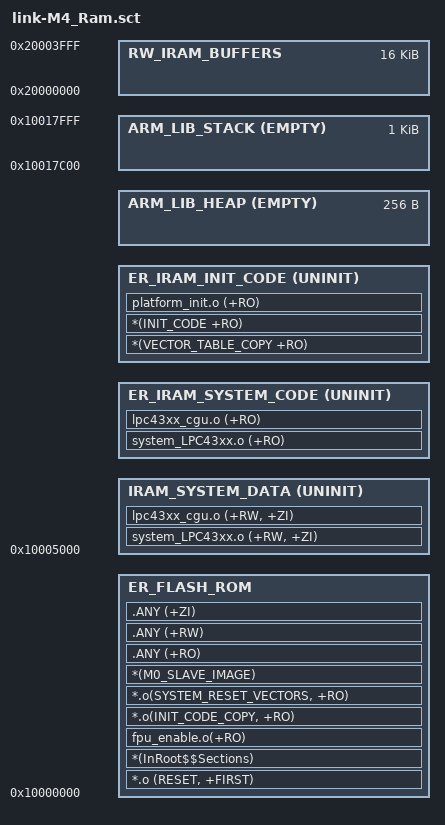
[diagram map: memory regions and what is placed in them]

LR_IRAM 0x10000000 0x18000  {    

  	; code
	ER_FLASH_ROM 0x10000000 {  
   		
		*.o (RESET, +FIRST)
		 
	 	; used as an alias for the ARM library functions 
		; (__main, __scatter, __dc, __*region$$Table etc)
		*(InRoot$$Sections)	 
		
		; enable the fpu as soon as possible if present
		fpu_enable.o(+RO)
		
		; this code copies the initialization routines in ram
		; these are needed to change the PLL settings, the EMC settings
		; are executed from ER_IRAM_SYSTEM_CODE, ER_IRAM_BOOT_CODE 
		*.o(INIT_CODE_COPY, +RO)
		
		; include all system reset vectors
		*.o(SYSTEM_RESET_VECTORS, +RO) 
		
		*(M0_SLAVE_IMAGE)
		
		.ANY (+RO)
		.ANY (+RW)
		.ANY (+ZI) 

	}
	
  	; "SystemData_noInit" section  
	IRAM_SYSTEM_DATA 0x10005000 UNINIT {
  	
		system_LPC43xx.o (+RW, +ZI)
		lpc43xx_cgu.o (+RW, +ZI)			  	
	}

	; these are the runtime locations for the PLL and EMC initialization routines
	; SYSTEM_CODE should likely be kept during the application's lifetime
	; scu and cgu functions could be needed later on
	ER_IRAM_SYSTEM_CODE +0 UNINIT { 

		system_LPC43xx.o (+RO)
		lpc43xx_cgu.o (+RO)
	}

	; these functions are used only during startup
	; eventually this RAM area could be reused during the application's lifetime
	ER_IRAM_INIT_CODE +0 UNINIT {

	   *(VECTOR_TABLE_COPY +RO)
	   *(INIT_CODE +RO)
	   platform_init.o (+RO)
	}

	; setup a heap using default region name for arm lib "ARM_LIB_HEAP"
	ARM_LIB_HEAP +0 EMPTY 0x100 {  

	}

	; setup the stack using default region name for arm lib "ARM_LIB_STACK" 
	; is growing backwards so will overlap is no space is available
	ARM_LIB_STACK 0x10018000 EMPTY -0x400 {	 

	}

	RW_IRAM_BUFFERS 0x20000000 0x4000 { ; rw buffers
  	
  	}
  
}






